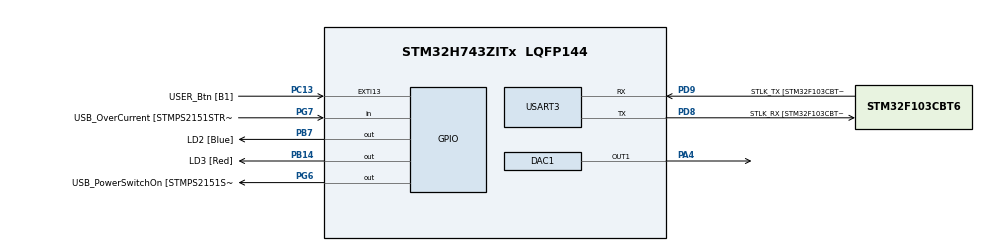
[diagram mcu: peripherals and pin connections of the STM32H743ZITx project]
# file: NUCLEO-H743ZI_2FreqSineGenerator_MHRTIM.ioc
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Mcu.Family=STM32H7
HRTIM.PreloadEnable-MasterTimer=HRTIM_PRELOAD_ENABLED
RCC.CortexFreq_Value=400000000
Dma.DAC1_CH1.0.Priority=DMA_PRIORITY_HIGH
PG6.Signal=GPIO_Output
Dma.DAC1_CH1.0.FIFOMode=DMA_FIFOMODE_DISABLE
RCC.HPRE=RCC_HCLK_DIV2
PH0-OSC_IN\ (PH0).Signal=RCC_OSC_IN
DAC1.DAC_Channel-DAC_OUT1_ExtAndInt=DAC_CHANNEL_1
PB14.GPIO_Label=LD3 [Red]
PG6.GPIO_Label=USB_PowerSwitchOn [STMPS2151STR_EN]
PC15-OSC32_OUT\ (OSC32_OUT).Mode=LSE-External-Oscillator
RCC.SYSCLKSourceVirtual=RCC_SYSCLKSOURCE_PLLCLK
PC13.GPIO_Label=USER_Btn [B1]
PB13.GPIO_Label=RMII_TXD1
PB13.Signal=ETH_TXD1
PG13.Signal=ETH_TXD0
PD9.Mode=Asynchronous
PG11.Signal=ETH_TX_EN
RCC.SYSCLKSource=RCC_SYSCLKSOURCE_PLLCLK
ProjectManager.StackSize=0x400
USART3.VirtualMode-Asynchronous=VM_ASYNC
PA12.Signal=USB_OTG_FS_DP
Dma.DAC1_CH1.0.SyncPolarity=HAL_DMAMUX_SYNC_NO_EVENT
RCC.HCLKFreq_Value=200000000
Dma.DAC1_CH1.0.EventEnable=DISABLE
RCC.APB2TimFreq_Value=216000000
PD8.Signal=USART3_TX
RCC.AHBFreq_Value=216000000
VP_HRTIM_VS_hrtimMasterTimerNoOutput.Mode=MasterTimer
RCC.HSE_VALUE=8000000
Dma.DAC1_CH1.0.SignalID=NONE
RCC.DIVM1=4
RCC.PLLMUL=RCC_PLL_MUL9
HRTIM.Periode_MASTER=100
PC4.GPIO_Label=RMII_RXD0
Dma.DAC1_CH1.0.Mode=DMA_CIRCULAR
PA10.GPIO_Label=USB_ID
PB7.Signal=GPIO_Output
PA8.Signal=USB_OTG_FS_SOF
RCC.APB3Freq_Value=100000000
PB7.GPIO_Label=LD2 [Blue]
Mcu.Package=LQFP144
RCC.D1PPRE=RCC_APB3_DIV2
PA2.GPIO_Label=RMII_MDIO
PA10.Signal=USB_OTG_FS_ID
Dma.DAC1_CH1.0.Instance=DMA1_Stream1
PC14-OSC32_IN\ (OSC32_IN).Mode=LSE-External-Oscillator
RCC.APB2CLKDivider=RCC_HCLK_DIV2
RCC.APB4Freq_Value=100000000
RCC.APB1TimFreq_Value=108000000
PG11.GPIO_Label=RMII_TX_EN
PC5.Signal=ETH_RXD1
Dma.Request0=DAC1_CH1
DAC1.DAC_Trigger-DAC_OUT1_ExtAndInt=DAC_TRIGGER_HR1_TRGO1
PH0-OSC_IN\ (PH0).Mode=HSE-External-Clock-Source
Dma.DAC1_CH1.0.PeriphInc=DMA_PINC_DISABLE
RCC.PLLSourceVirtual=RCC_PLLSOURCE_HSE
RCC.DIVQ1=4
PG7.Signal=GPIO_Input
PD9.GPIO_Label=STLK_TX [STM32F103CBT6_PA2]
PC13.Signal=GPXTI13
PA9.GPIO_Label=USB_VBUS
PC4.Signal=ETH_RXD0
RCC.D2PPRE2=RCC_APB2_DIV2
PA11.GPIO_Label=USB_DM
RCC.D2PPRE1=RCC_APB1_DIV2
PD9.Signal=USART3_RX
HRTIM.RepetitionUpdate-MasterTimer=HRTIM_UPDATEONREPETITION_ENABLED
HRTIM.DACSynchro-MasterTimer=HRTIM_DACSYNC_DACTRIGOUT_1
NVIC.DMA1_Stream1_IRQn=true\:0\:0\:false\:false\:true\:false\:true
RCC.APB1CLKDivider=RCC_HCLK_DIV4
PG13.GPIO_Label=RMII_TXD0
PA12.GPIO_Label=USB_DP
RCC.PWR_Regulator_Voltage_Scale=PWR_REGULATOR_VOLTAGE_SCALE1
PH1-OSC_OUT\ (PH1).Signal=RCC_OSC_OUT
PD8.GPIO_Label=STLK_RX [STM32F103CBT6_PA3]
PA8.GPIO_Label=USB_SOF [TP1]
ProjectManager.TargetToolchain=STM32CubeIDE
PC15-OSC32_OUT\ (OSC32_OUT).Signal=RCC_OSC32_OUT
SH.COMP_DAC11_group.0=DAC1_OUT1,DAC_OUT1_ExtAndInt
PA9.Signal=USB_OTG_FS_VBUS
DAC1.DAC_SampleAndHold-DAC_OUT1_ExtAndInt=DAC_SAMPLEANDHOLD_DISABLE
RCC.DIVN1=400
RCC.USBFreq_Value=200000000
PD8.Mode=Asynchronous
PA1.Signal=ETH_REF_CLK
PB14.Signal=GPIO_Output
Dma.DAC1_CH1.0.MemDataAlignment=DMA_MDATAALIGN_WORD
board=NUCLEO-H743ZI
RCC.VCOOutputFreq_Value=432000000
RCC.APB2Freq_Value=100000000
RCC.PRESCALERUSB=RCC_USBCLKSOURCE_PLL_DIV1_5
PG7.GPIO_Label=USB_OverCurrent [STMPS2151STR_FAULT]
RCC.ADCFreq_Value=16125000
PA1.GPIO_Label=RMII_REF_CLK
PC1.GPIO_Label=RMII_MDC
Dma.DAC1_CH1.0.PeriphDataAlignment=DMA_PDATAALIGN_WORD
Dma.DAC1_CH1.0.MemInc=DMA_MINC_ENABLE
Mcu.Name=STM32H743ZITx
Dma.DAC1_CH1.0.SyncEnable=DISABLE
PA2.Signal=ETH_MDIO
RCC.48MHZClocksFreq_Value=24000000
PA4.Signal=COMP_DAC11_group
RCC.SYSCLKFreq_VALUE=400000000
PA7.GPIO_Label=RMII_CRS_DV
PC14-OSC32_IN\ (OSC32_IN).Signal=RCC_OSC32_IN
PC5.GPIO_Label=RMII_RXD1
PA11.Signal=USB_OTG_FS_DM
ProjectManager.HeapSize=0x200
RCC.HSI_VALUE=64000000
RCC.PLLQ=9
NVIC.PriorityGroup=NVIC_PRIORITYGROUP_4
PH0-OSC_IN\ (PH0).GPIO_Label=MCO
RCC.PLLM=25
RCC.PLLN=432
Dma.DAC1_CH1.0.SyncRequestNumber=1
RCC.D3PPRE=RCC_APB4_DIV2
Dma.DAC1_CH1.0.SyncSignalID=NONE
RCC.APB1Freq_Value=100000000
PC1.Signal=ETH_MDC
Dma.DAC1_CH1.0.Direction=DMA_MEMORY_TO_PERIPH
DAC1.WaveGeneration-DAC_OUT1_ExtAndInt=DISABLE
Dma.DAC1_CH1.0.Polarity=HAL_DMAMUX_REQ_GEN_RISING
PA7.Signal=ETH_CRS_DV
Dma.DAC1_CH1.0.RequestNumber=1

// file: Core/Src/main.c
/* USER CODE BEGIN Header */
/**
  ******************************************************************************
  * @file           : main.c
  * @brief          : Main program body
  ******************************************************************************
  * @attention
  *
  * <h2><center>&copy; Copyright (c) 2021 STMicroelectronics.
  * All rights reserved.</center></h2>
  *
  * This software component is licensed by ST under BSD 3-Clause license,
  * the "License"; You may not use this file except in compliance with the
  * License. You may obtain a copy of the License at:
  *                        opensource.org/licenses/BSD-3-Clause
  *
  ******************************************************************************
  */
/* USER CODE END Header */
#include "main.h"

/* USER CODE BEGIN Includes */

#include "waveforms.h"

/* USER CODE END Includes */

DAC_HandleTypeDef hdac1;
DMA_HandleTypeDef hdma_dac1_ch1;

HRTIM_HandleTypeDef hhrtim;

UART_HandleTypeDef huart3;

void SystemClock_Config(void);
static void MX_GPIO_Init(void);
static void MX_DMA_Init(void);
static void MX_USART3_UART_Init(void);
static void MX_DAC1_Init(void);
static void MX_HRTIM_Init(void);

int main(void)
{

  /* MCU Configuration--------------------------------------------------------*/

  /* Reset of all peripherals, Initializes the Flash interface and the Systick. */
  HAL_Init();

  /* Configure the system clock */
  SystemClock_Config();

  /* Initialize all configured peripherals */
  MX_GPIO_Init();
  MX_DMA_Init();
  MX_USART3_UART_Init();
  MX_DAC1_Init();
  MX_HRTIM_Init();
  /* USER CODE BEGIN 2 */

//  /*## Enable DAC Channel1 ################################################################*/
//  if (HAL_DAC_Start(&hdac1, DAC_CHANNEL_1) != HAL_OK)
//  {
//    /* Start Error */
//    Error_Handler();
//  }

  /*## Enable DAC DMA Channel1 ################################################################*/
  if (HAL_OK != HAL_DAC_Start_DMA(&hdac1, DAC_CHANNEL_1,
			   (uint32_t*)MySine2000, (uint32_t*)MySine2000_SIZE, (uint32_t*)DAC_ALIGN_12B_R))
  {
    /* Start Error */
    Error_Handler();
  }

  /*## Start HRTIM counter ###################################################################*/
	if (HAL_HRTIM_WaveformCounterStart(&hhrtim, HRTIM_TIMERID_MASTER) != HAL_OK)
  {
    /* PWM Generation Error */
    Error_Handler();
  }

  /* USER CODE END 2 */

  /* Infinite loop */
  while (1)
  {

  }
}

void SystemClock_Config(void)
{
  RCC_OscInitTypeDef RCC_OscInitStruct = {0};
  RCC_ClkInitTypeDef RCC_ClkInitStruct = {0};

  /** Supply configuration update enable
  */
  HAL_PWREx_ConfigSupply(PWR_LDO_SUPPLY);
  /** Configure the main internal regulator output voltage
  */
  __HAL_PWR_VOLTAGESCALING_CONFIG(PWR_REGULATOR_VOLTAGE_SCALE1);

  while(!__HAL_PWR_GET_FLAG(PWR_FLAG_VOSRDY)) {}
  /** Initializes the RCC Oscillators according to the specified parameters
  * in the RCC_OscInitTypeDef structure.
  */
  RCC_OscInitStruct.OscillatorType = RCC_OSCILLATORTYPE_HSE;
  RCC_OscInitStruct.HSEState = RCC_HSE_BYPASS;
  RCC_OscInitStruct.PLL.PLLState = RCC_PLL_ON;
  RCC_OscInitStruct.PLL.PLLSource = RCC_PLLSOURCE_HSE;
  RCC_OscInitStruct.PLL.PLLM = 4;
  RCC_OscInitStruct.PLL.PLLN = 400;
  RCC_OscInitStruct.PLL.PLLP = 2;
  RCC_OscInitStruct.PLL.PLLQ = 4;
  RCC_OscInitStruct.PLL.PLLR = 2;
  RCC_OscInitStruct.PLL.PLLRGE = RCC_PLL1VCIRANGE_1;
  RCC_OscInitStruct.PLL.PLLVCOSEL = RCC_PLL1VCOWIDE;
  RCC_OscInitStruct.PLL.PLLFRACN = 0;
  if (HAL_RCC_OscConfig(&RCC_OscInitStruct) != HAL_OK)
  {
    Error_Handler();
  }
  /** Initializes the CPU, AHB and APB buses clocks
  */
  RCC_ClkInitStruct.ClockType = RCC_CLOCKTYPE_HCLK|RCC_CLOCKTYPE_SYSCLK
                              |RCC_CLOCKTYPE_PCLK1|RCC_CLOCKTYPE_PCLK2
                              |RCC_CLOCKTYPE_D3PCLK1|RCC_CLOCKTYPE_D1PCLK1;
  RCC_ClkInitStruct.SYSCLKSource = RCC_SYSCLKSOURCE_PLLCLK;
  RCC_ClkInitStruct.SYSCLKDivider = RCC_SYSCLK_DIV1;
  RCC_ClkInitStruct.AHBCLKDivider = RCC_HCLK_DIV2;
  RCC_ClkInitStruct.APB3CLKDivider = RCC_APB3_DIV2;
  RCC_ClkInitStruct.APB1CLKDivider = RCC_APB1_DIV2;
  RCC_ClkInitStruct.APB2CLKDivider = RCC_APB2_DIV2;
  RCC_ClkInitStruct.APB4CLKDivider = RCC_APB4_DIV2;

  if (HAL_RCC_ClockConfig(&RCC_ClkInitStruct, FLASH_LATENCY_2) != HAL_OK)
  {
    Error_Handler();
  }
}

static void MX_DAC1_Init(void)
{

  DAC_ChannelConfTypeDef sConfig = {0};

  /** DAC Initialization
  */
  hdac1.Instance = DAC1;
  if (HAL_DAC_Init(&hdac1) != HAL_OK)
  {
    Error_Handler();
  }
  /** DAC channel OUT1 config
  */
  sConfig.DAC_SampleAndHold = DAC_SAMPLEANDHOLD_DISABLE;
  sConfig.DAC_Trigger = DAC_TRIGGER_HR1_TRGO1;
  sConfig.DAC_OutputBuffer = DAC_OUTPUTBUFFER_ENABLE;
  sConfig.DAC_ConnectOnChipPeripheral = DAC_CHIPCONNECT_ENABLE;
  sConfig.DAC_UserTrimming = DAC_TRIMMING_FACTORY;
  if (HAL_DAC_ConfigChannel(&hdac1, &sConfig, DAC_CHANNEL_1) != HAL_OK)
  {
    Error_Handler();
  }

}

static void MX_HRTIM_Init(void)
{

  HRTIM_TimeBaseCfgTypeDef pTimeBaseCfg = {0};
  HRTIM_TimerCfgTypeDef pTimerCfg = {0};

  hhrtim.Instance = HRTIM1;
  hhrtim.Init.HRTIMInterruptResquests = HRTIM_IT_NONE;
  hhrtim.Init.SyncOptions = HRTIM_SYNCOPTION_NONE;
  if (HAL_HRTIM_Init(&hhrtim) != HAL_OK)
  {
    Error_Handler();
  }
  pTimeBaseCfg.Period = 100;
  pTimeBaseCfg.RepetitionCounter = 0x00;
  pTimeBaseCfg.PrescalerRatio = HRTIM_PRESCALERRATIO_DIV1;
  pTimeBaseCfg.Mode = HRTIM_MODE_CONTINUOUS;
  if (HAL_HRTIM_TimeBaseConfig(&hhrtim, HRTIM_TIMERINDEX_MASTER, &pTimeBaseCfg) != HAL_OK)
  {
    Error_Handler();
  }
  pTimerCfg.InterruptRequests = HRTIM_MASTER_IT_NONE;
  pTimerCfg.DMARequests = HRTIM_MASTER_DMA_NONE;
  pTimerCfg.DMASrcAddress = 0x0000;
  pTimerCfg.DMADstAddress = 0x0000;
  pTimerCfg.DMASize = 0x1;
  pTimerCfg.HalfModeEnable = HRTIM_HALFMODE_DISABLED;
  pTimerCfg.StartOnSync = HRTIM_SYNCSTART_DISABLED;
  pTimerCfg.ResetOnSync = HRTIM_SYNCRESET_DISABLED;
  pTimerCfg.DACSynchro = HRTIM_DACSYNC_DACTRIGOUT_1;
  pTimerCfg.PreloadEnable = HRTIM_PRELOAD_ENABLED;
  pTimerCfg.UpdateGating = HRTIM_UPDATEGATING_INDEPENDENT;
  pTimerCfg.BurstMode = HRTIM_TIMERBURSTMODE_MAINTAINCLOCK;
  pTimerCfg.RepetitionUpdate = HRTIM_UPDATEONREPETITION_ENABLED;
  if (HAL_HRTIM_WaveformTimerConfig(&hhrtim, HRTIM_TIMERINDEX_MASTER, &pTimerCfg) != HAL_OK)
  {
    Error_Handler();
  }

}

static void MX_USART3_UART_Init(void)
{

  huart3.Instance = USART3;
  huart3.Init.BaudRate = 115200;
  huart3.Init.WordLength = UART_WORDLENGTH_8B;
  huart3.Init.StopBits = UART_STOPBITS_1;
  huart3.Init.Parity = UART_PARITY_NONE;
  huart3.Init.Mode = UART_MODE_TX_RX;
  huart3.Init.HwFlowCtl = UART_HWCONTROL_NONE;
  huart3.Init.OverSampling = UART_OVERSAMPLING_16;
  huart3.Init.OneBitSampling = UART_ONE_BIT_SAMPLE_DISABLE;
  huart3.Init.ClockPrescaler = UART_PRESCALER_DIV1;
  huart3.AdvancedInit.AdvFeatureInit = UART_ADVFEATURE_NO_INIT;
  if (HAL_UART_Init(&huart3) != HAL_OK)
  {
    Error_Handler();
  }
  if (HAL_UARTEx_SetTxFifoThreshold(&huart3, UART_TXFIFO_THRESHOLD_1_8) != HAL_OK)
  {
    Error_Handler();
  }
  if (HAL_UARTEx_SetRxFifoThreshold(&huart3, UART_RXFIFO_THRESHOLD_1_8) != HAL_OK)
  {
    Error_Handler();
  }
  if (HAL_UARTEx_DisableFifoMode(&huart3) != HAL_OK)
  {
    Error_Handler();
  }

}

static void MX_DMA_Init(void)
{

  /* DMA controller clock enable */
  __HAL_RCC_DMA1_CLK_ENABLE();

  /* DMA interrupt init */
  /* DMA1_Stream1_IRQn interrupt configuration */
  HAL_NVIC_SetPriority(DMA1_Stream1_IRQn, 0, 0);
  HAL_NVIC_EnableIRQ(DMA1_Stream1_IRQn);

}

static void MX_GPIO_Init(void)
{
  GPIO_InitTypeDef GPIO_InitStruct = {0};

  /* GPIO Ports Clock Enable */
  __HAL_RCC_GPIOC_CLK_ENABLE();
  __HAL_RCC_GPIOH_CLK_ENABLE();
  __HAL_RCC_GPIOA_CLK_ENABLE();
  __HAL_RCC_GPIOB_CLK_ENABLE();
  __HAL_RCC_GPIOD_CLK_ENABLE();
  __HAL_RCC_GPIOG_CLK_ENABLE();

  /*Configure GPIO pin Output Level */
  HAL_GPIO_WritePin(GPIOB, LD3_Pin|LD2_Pin, GPIO_PIN_RESET);

  /*Configure GPIO pin Output Level */
  HAL_GPIO_WritePin(USB_PowerSwitchOn_GPIO_Port, USB_PowerSwitchOn_Pin, GPIO_PIN_RESET);

  /*Configure GPIO pin : USER_Btn_Pin */
  GPIO_InitStruct.Pin = USER_Btn_Pin;
  GPIO_InitStruct.Mode = GPIO_MODE_IT_RISING;
  GPIO_InitStruct.Pull = GPIO_NOPULL;
  HAL_GPIO_Init(USER_Btn_GPIO_Port, &GPIO_InitStruct);

  /*Configure GPIO pins : RMII_MDC_Pin RMII_RXD0_Pin RMII_RXD1_Pin */
  GPIO_InitStruct.Pin = RMII_MDC_Pin|RMII_RXD0_Pin|RMII_RXD1_Pin;
  GPIO_InitStruct.Mode = GPIO_MODE_AF_PP;
  GPIO_InitStruct.Pull = GPIO_NOPULL;
  GPIO_InitStruct.Speed = GPIO_SPEED_FREQ_LOW;
  GPIO_InitStruct.Alternate = GPIO_AF11_ETH;
  HAL_GPIO_Init(GPIOC, &GPIO_InitStruct);

  /*Configure GPIO pins : RMII_REF_CLK_Pin RMII_MDIO_Pin RMII_CRS_DV_Pin */
  GPIO_InitStruct.Pin = RMII_REF_CLK_Pin|RMII_MDIO_Pin|RMII_CRS_DV_Pin;
  GPIO_InitStruct.Mode = GPIO_MODE_AF_PP;
  GPIO_InitStruct.Pull = GPIO_NOPULL;
  GPIO_InitStruct.Speed = GPIO_SPEED_FREQ_LOW;
  GPIO_InitStruct.Alternate = GPIO_AF11_ETH;
  HAL_GPIO_Init(GPIOA, &GPIO_InitStruct);

  /*Configure GPIO pin : RMII_TXD1_Pin */
  GPIO_InitStruct.Pin = RMII_TXD1_Pin;
  GPIO_InitStruct.Mode = GPIO_MODE_AF_PP;
  GPIO_InitStruct.Pull = GPIO_NOPULL;
  GPIO_InitStruct.Speed = GPIO_SPEED_FREQ_LOW;
  GPIO_InitStruct.Alternate = GPIO_AF11_ETH;
  HAL_GPIO_Init(RMII_TXD1_GPIO_Port, &GPIO_InitStruct);

  /*Configure GPIO pins : LD3_Pin LD2_Pin */
  GPIO_InitStruct.Pin = LD3_Pin|LD2_Pin;
  GPIO_InitStruct.Mode = GPIO_MODE_OUTPUT_PP;
  GPIO_InitStruct.Pull = GPIO_NOPULL;
  GPIO_InitStruct.Speed = GPIO_SPEED_FREQ_LOW;
  HAL_GPIO_Init(GPIOB, &GPIO_InitStruct);

  /*Configure GPIO pin : USB_PowerSwitchOn_Pin */
  GPIO_InitStruct.Pin = USB_PowerSwitchOn_Pin;
  GPIO_InitStruct.Mode = GPIO_MODE_OUTPUT_PP;
  GPIO_InitStruct.Pull = GPIO_NOPULL;
  GPIO_InitStruct.Speed = GPIO_SPEED_FREQ_LOW;
  HAL_GPIO_Init(USB_PowerSwitchOn_GPIO_Port, &GPIO_InitStruct);

  /*Configure GPIO pin : USB_OverCurrent_Pin */
  GPIO_InitStruct.Pin = USB_OverCurrent_Pin;
  GPIO_InitStruct.Mode = GPIO_MODE_INPUT;
  GPIO_InitStruct.Pull = GPIO_NOPULL;
  HAL_GPIO_Init(USB_OverCurrent_GPIO_Port, &GPIO_InitStruct);

  /*Configure GPIO pins : USB_SOF_Pin USB_ID_Pin USB_DM_Pin USB_DP_Pin */
  GPIO_InitStruct.Pin = USB_SOF_Pin|USB_ID_Pin|USB_DM_Pin|USB_DP_Pin;
  GPIO_InitStruct.Mode = GPIO_MODE_AF_PP;
  GPIO_InitStruct.Pull = GPIO_NOPULL;
  GPIO_InitStruct.Speed = GPIO_SPEED_FREQ_LOW;
  GPIO_InitStruct.Alternate = GPIO_AF10_OTG1_FS;
  HAL_GPIO_Init(GPIOA, &GPIO_InitStruct);

  /*Configure GPIO pins : RMII_TX_EN_Pin RMII_TXD0_Pin */
  GPIO_InitStruct.Pin = RMII_TX_EN_Pin|RMII_TXD0_Pin;
  GPIO_InitStruct.Mode = GPIO_MODE_AF_PP;
  GPIO_InitStruct.Pull = GPIO_NOPULL;
  GPIO_InitStruct.Speed = GPIO_SPEED_FREQ_LOW;
  GPIO_InitStruct.Alternate = GPIO_AF11_ETH;
  HAL_GPIO_Init(GPIOG, &GPIO_InitStruct);

}

void Error_Handler(void)
{
  __disable_irq();
  while (1)
  {
  }
}

/************************ (C) COPYRIGHT STMicroelectronics *****END OF FILE****/
